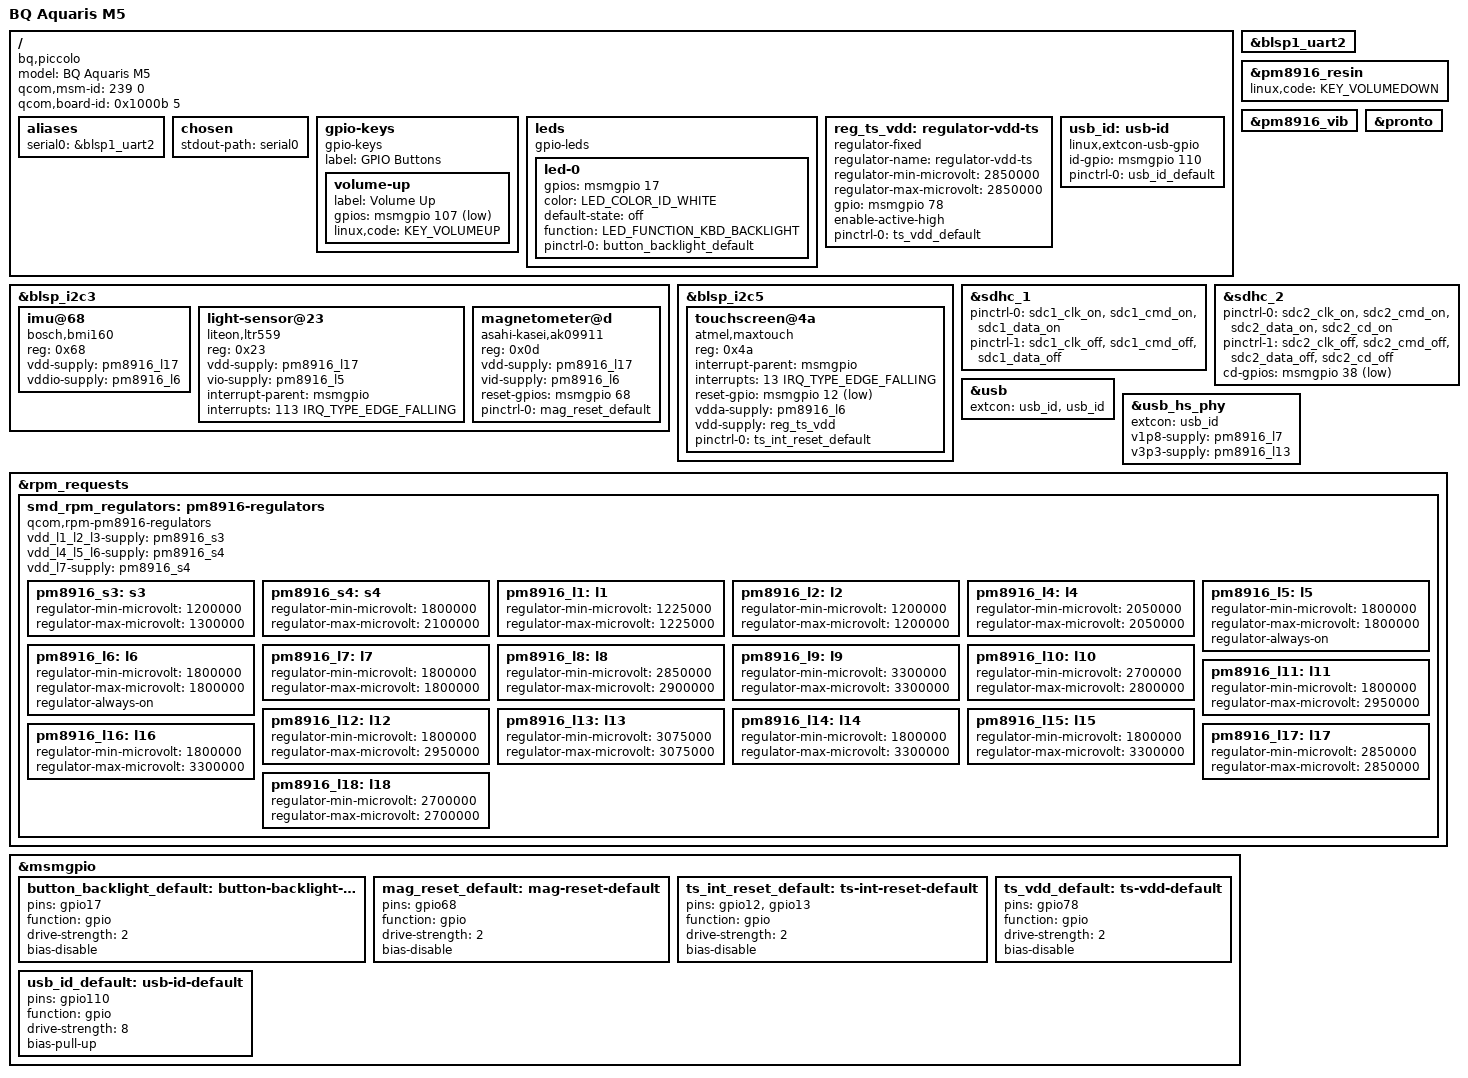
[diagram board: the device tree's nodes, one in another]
// SPDX-License-Identifier: GPL-2.0-only

/dts-v1/;

#include "msm8939.dtsi"
#include "pm8916.dtsi"
#include "arm/qcom-msm8939-no-psci.dtsi"
#include <dt-bindings/gpio/gpio.h>
#include <dt-bindings/input/input.h>
#include <dt-bindings/interrupt-controller/irq.h>
#include <dt-bindings/leds/common.h>

/ {
	model = "BQ Aquaris M5";
	compatible = "bq,piccolo", "qcom,msm8939", "qcom,msm8939-qrd-skuk", "qcom,qrd";
	qcom,msm-id = <239 0>;
	qcom,board-id = <0x1000b 5>;

	aliases {
		serial0 = &blsp1_uart2;
	};

	chosen {
		stdout-path = "serial0";
	};

	gpio-keys {
		compatible = "gpio-keys";

		pinctrl-names = "default";

		label = "GPIO Buttons";

		volume-up {
			label = "Volume Up";
			gpios = <&msmgpio 107 GPIO_ACTIVE_LOW>;
			linux,code = <KEY_VOLUMEUP>;
		};
	};

	leds {
		compatible = "gpio-leds";

		led-0 {
			gpios = <&msmgpio 17 GPIO_ACTIVE_HIGH>;
			color = <LED_COLOR_ID_WHITE>;
			default-state = "off";
			function = LED_FUNCTION_KBD_BACKLIGHT;

			pinctrl-names = "default";
			pinctrl-0 = <&button_backlight_default>;
		};
	};

	reg_ts_vdd: regulator-vdd-ts {
		compatible = "regulator-fixed";
		regulator-name = "regulator-vdd-ts";
		regulator-min-microvolt = <2850000>;
		regulator-max-microvolt = <2850000>;

		gpio = <&msmgpio 78 GPIO_ACTIVE_HIGH>;
		enable-active-high;

		pinctrl-names = "default";
		pinctrl-0 = <&ts_vdd_default>;
	};

	usb_id: usb-id {
		compatible = "linux,extcon-usb-gpio";
		id-gpio = <&msmgpio 110 GPIO_ACTIVE_HIGH>;
		pinctrl-names = "default";
		pinctrl-0 = <&usb_id_default>;
	};

};

&blsp_i2c3 {
	status = "okay";

	imu@68 {
		compatible = "bosch,bmi160";
		reg = <0x68>;

		vdd-supply = <&pm8916_l17>;
		vddio-supply = <&pm8916_l6>;
	};

	light-sensor@23 {
		compatible = "liteon,ltr559";
		reg = <0x23>;
		vdd-supply = <&pm8916_l17>;
		vio-supply = <&pm8916_l5>;

		interrupt-parent = <&msmgpio>;
		interrupts = <113 IRQ_TYPE_EDGE_FALLING>;
	};

	magnetometer@d {
		compatible = "asahi-kasei,ak09911";
		reg = <0x0d>;

		vdd-supply = <&pm8916_l17>;
		vid-supply = <&pm8916_l6>;

		reset-gpios = <&msmgpio 68 GPIO_ACTIVE_HIGH>;

		pinctrl-names = "default";
		pinctrl-0 = <&mag_reset_default>;
	};
};

&blsp_i2c5 {
	status = "okay";

	touchscreen@4a {
		compatible = "atmel,maxtouch";
		reg = <0x4a>;

		interrupt-parent = <&msmgpio>;
		interrupts = <13 IRQ_TYPE_EDGE_FALLING>;

		reset-gpio = <&msmgpio 12 GPIO_ACTIVE_LOW>;

		vdda-supply = <&pm8916_l6>;
		vdd-supply = <&reg_ts_vdd>;

		pinctrl-names = "default";
		pinctrl-0 = <&ts_int_reset_default>;
	};
};

&blsp1_uart2 {
	status = "okay";
};

&pm8916_resin {
	status = "okay";
	linux,code = <KEY_VOLUMEDOWN>;
};

&pm8916_vib {
	status = "okay";
};

&pronto {
	status = "okay";
};

&sdhc_1 {
	status = "okay";

	pinctrl-names = "default", "sleep";
	pinctrl-0 = <&sdc1_clk_on &sdc1_cmd_on &sdc1_data_on>;
	pinctrl-1 = <&sdc1_clk_off &sdc1_cmd_off &sdc1_data_off>;
};

&sdhc_2 {
	status = "okay";

	pinctrl-names = "default", "sleep";
	pinctrl-0 = <&sdc2_clk_on &sdc2_cmd_on &sdc2_data_on &sdc2_cd_on>;
	pinctrl-1 = <&sdc2_clk_off &sdc2_cmd_off &sdc2_data_off &sdc2_cd_off>;

	cd-gpios = <&msmgpio 38 GPIO_ACTIVE_LOW>;
};

&usb {
	status = "okay";
	extcon = <&usb_id>, <&usb_id>;
};

&usb_hs_phy {
	extcon = <&usb_id>;
	v1p8-supply = <&pm8916_l7>;
	v3p3-supply = <&pm8916_l13>;
};

&rpm_requests {
	smd_rpm_regulators: pm8916-regulators {
		compatible = "qcom,rpm-pm8916-regulators";
		vdd_l1_l2_l3-supply = <&pm8916_s3>;
		vdd_l4_l5_l6-supply = <&pm8916_s4>;
		vdd_l7-supply = <&pm8916_s4>;

		pm8916_s3: s3 {
			regulator-min-microvolt = <1200000>;
			regulator-max-microvolt = <1300000>;
		};

		pm8916_s4: s4 {
			regulator-min-microvolt = <1800000>;
			regulator-max-microvolt = <2100000>;
		};

		pm8916_l1: l1 {
			regulator-min-microvolt = <1225000>;
			regulator-max-microvolt = <1225000>;
		};

		pm8916_l2: l2 {
			regulator-min-microvolt = <1200000>;
			regulator-max-microvolt = <1200000>;
		};

		pm8916_l4: l4 {
			regulator-min-microvolt = <2050000>;
			regulator-max-microvolt = <2050000>;
		};

		pm8916_l5: l5 {
			regulator-min-microvolt = <1800000>;
			regulator-max-microvolt = <1800000>;
			regulator-always-on; /* keep it ? */
		};

		pm8916_l6: l6 {
			regulator-min-microvolt = <1800000>;
			regulator-max-microvolt = <1800000>;
			regulator-always-on;
		};

		pm8916_l7: l7 {
			regulator-min-microvolt = <1800000>;
			regulator-max-microvolt = <1800000>;
		};

		pm8916_l8: l8 {
			regulator-min-microvolt = <2850000>;
			regulator-max-microvolt = <2900000>;
		};

		pm8916_l9: l9 {
			regulator-min-microvolt = <3300000>;
			regulator-max-microvolt = <3300000>;
		};

		pm8916_l10: l10 {
			regulator-min-microvolt = <2700000>;
			regulator-max-microvolt = <2800000>;
		};

		pm8916_l11: l11 {
			regulator-min-microvolt = <1800000>;
			regulator-max-microvolt = <2950000>;
		};

		pm8916_l12: l12 {
			regulator-min-microvolt = <1800000>;
			regulator-max-microvolt = <2950000>;
		};

		pm8916_l13: l13 {
			regulator-min-microvolt = <3075000>;
			regulator-max-microvolt = <3075000>;
		};

		pm8916_l14: l14 {
			regulator-min-microvolt = <1800000>;
			regulator-max-microvolt = <3300000>;
		};

		pm8916_l15: l15 {
			regulator-min-microvolt = <1800000>;
			regulator-max-microvolt = <3300000>;
		};

		pm8916_l16: l16 {
			regulator-min-microvolt = <1800000>;
			regulator-max-microvolt = <3300000>;
		};

		pm8916_l17: l17 {
			regulator-min-microvolt = <2850000>;
			regulator-max-microvolt = <2850000>;
		};

		pm8916_l18: l18 {
			regulator-min-microvolt = <2700000>;
			regulator-max-microvolt = <2700000>;
		};
	};
};

&msmgpio {
	button_backlight_default: button-backlight-default {
		pins = "gpio17";
		function = "gpio";

		drive-strength = <2>;
		bias-disable;
	};

	mag_reset_default: mag-reset-default {
		pins = "gpio68";
		function = "gpio";

		drive-strength = <2>;
		bias-disable;
	};

	ts_int_reset_default: ts-int-reset-default {
		pins = "gpio12", "gpio13";
		function = "gpio";

		drive-strength = <2>;
		bias-disable;
	};

	ts_vdd_default: ts-vdd-default {
		pins = "gpio78";
		function = "gpio";

		drive-strength = <2>;
		bias-disable;
	};

	usb_id_default: usb-id-default {
		pins = "gpio110";
		function = "gpio";

		drive-strength = <8>;
		bias-pull-up;
	};
};
